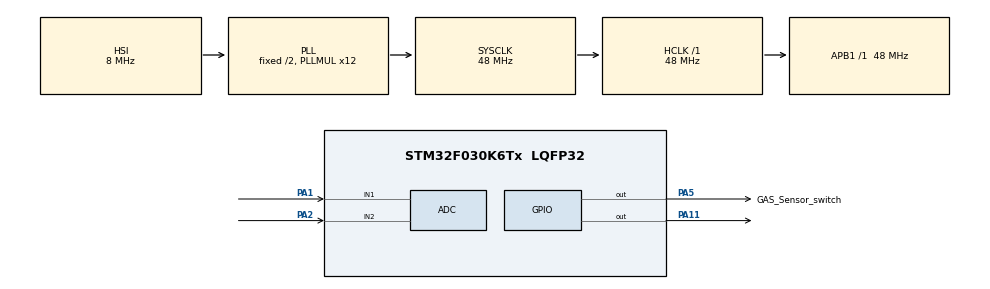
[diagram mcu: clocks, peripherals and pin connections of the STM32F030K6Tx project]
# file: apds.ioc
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ADC.Overrun=ADC_OVR_DATA_OVERWRITTEN
ADC.SamplingTime=ADC_SAMPLETIME_28CYCLES_5
Mcu.Family=STM32F0
Mcu.Name=STM32F030K6Tx
Mcu.Package=LQFP32
PA1.Mode=IN1
PA1.Signal=ADC_IN1
PA11.Signal=GPIO_Output
PA13.Mode=Serial_Wire
PA13.Signal=SYS_SWDIO
PA14.Mode=Serial_Wire
PA14.Signal=SYS_SWCLK
PA2.Mode=IN2
PA2.Signal=ADC_IN2
PA5.GPIO_Label=GAS_Sensor_switch
PA5.Signal=GPIO_Output
ProjectManager.HeapSize=0x200
ProjectManager.StackSize=0x400
ProjectManager.TargetToolchain=STM32CubeIDE
RCC.AHBFreq_Value=48000000
RCC.APB1Freq_Value=48000000
RCC.APB1TimFreq_Value=48000000
RCC.HCLKFreq_Value=48000000
RCC.PLLMUL=RCC_PLL_MUL12
RCC.SYSCLKFreq_VALUE=48000000
RCC.SYSCLKSource=RCC_SYSCLKSOURCE_PLLCLK
VP_ADC_Vref_Input.Mode=IN-Vrefint
board=custom

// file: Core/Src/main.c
/* USER CODE BEGIN Header */
/**
  ******************************************************************************
  * @file           : main.c
  * @brief          : Main program body
  ******************************************************************************
  * @attention
  *
  * <h2><center>&copy; Copyright (c) 2024 STMicroelectronics.
  * All rights reserved.</center></h2>
  *
  * This software component is licensed by ST under BSD 3-Clause license,
  * the "License"; You may not use this file except in compliance with the
  * License. You may obtain a copy of the License at:
  *                        opensource.org/licenses/BSD-3-Clause
  *
  ******************************************************************************
  */
/* USER CODE END Header */
#include "main.h"
#include "adc.h"
#include "gpio.h"

/* USER CODE BEGIN Includes */
#include "meas.h"
/* USER CODE END Includes */

void SystemClock_Config(void);

int main(void)
{

  /* MCU Configuration--------------------------------------------------------*/

  /* Reset of all peripherals, Initializes the Flash interface and the Systick. */
  HAL_Init();

  /* Configure the system clock */
  SystemClock_Config();

  /* Initialize all configured peripherals */
  MX_GPIO_Init();
  MX_ADC_Init();
  /* USER CODE BEGIN 2 */
//  HAL_ADC_Start(&hadc);
  volatile uint32_t val = 0;
  volatile double temp = 0;
  volatile double temp2 = 0;
  HAL_ADCEx_Calibration_Start(&hadc);
  init_sensors();
  /* USER CODE END 2 */

  /* Infinite loop */
  while (1)
  {

    /* USER CODE BEGIN 3 */
	  measure(GAS);
	  HAL_Delay(10000);
	  measure(TEMP);
	  HAL_Delay(10000);
  }
  /* USER CODE END 3 */
}

void SystemClock_Config(void)
{
  RCC_OscInitTypeDef RCC_OscInitStruct = {0};
  RCC_ClkInitTypeDef RCC_ClkInitStruct = {0};

  /** Initializes the RCC Oscillators according to the specified parameters
  * in the RCC_OscInitTypeDef structure.
  */
  RCC_OscInitStruct.OscillatorType = RCC_OSCILLATORTYPE_HSI|RCC_OSCILLATORTYPE_HSI14;
  RCC_OscInitStruct.HSIState = RCC_HSI_ON;
  RCC_OscInitStruct.HSI14State = RCC_HSI14_ON;
  RCC_OscInitStruct.HSICalibrationValue = RCC_HSICALIBRATION_DEFAULT;
  RCC_OscInitStruct.HSI14CalibrationValue = 16;
  RCC_OscInitStruct.PLL.PLLState = RCC_PLL_ON;
  RCC_OscInitStruct.PLL.PLLSource = RCC_PLLSOURCE_HSI;
  RCC_OscInitStruct.PLL.PLLMUL = RCC_PLL_MUL12;
  RCC_OscInitStruct.PLL.PREDIV = RCC_PREDIV_DIV1;
  if (HAL_RCC_OscConfig(&RCC_OscInitStruct) != HAL_OK)
  {
    Error_Handler();
  }
  /** Initializes the CPU, AHB and APB buses clocks
  */
  RCC_ClkInitStruct.ClockType = RCC_CLOCKTYPE_HCLK|RCC_CLOCKTYPE_SYSCLK
                              |RCC_CLOCKTYPE_PCLK1;
  RCC_ClkInitStruct.SYSCLKSource = RCC_SYSCLKSOURCE_PLLCLK;
  RCC_ClkInitStruct.AHBCLKDivider = RCC_SYSCLK_DIV1;
  RCC_ClkInitStruct.APB1CLKDivider = RCC_HCLK_DIV1;

  if (HAL_RCC_ClockConfig(&RCC_ClkInitStruct, FLASH_LATENCY_1) != HAL_OK)
  {
    Error_Handler();
  }
}

void Error_Handler(void)
{
  __disable_irq();
  while (1)
  {
  }
}

/************************ (C) COPYRIGHT STMicroelectronics *****END OF FILE****/
